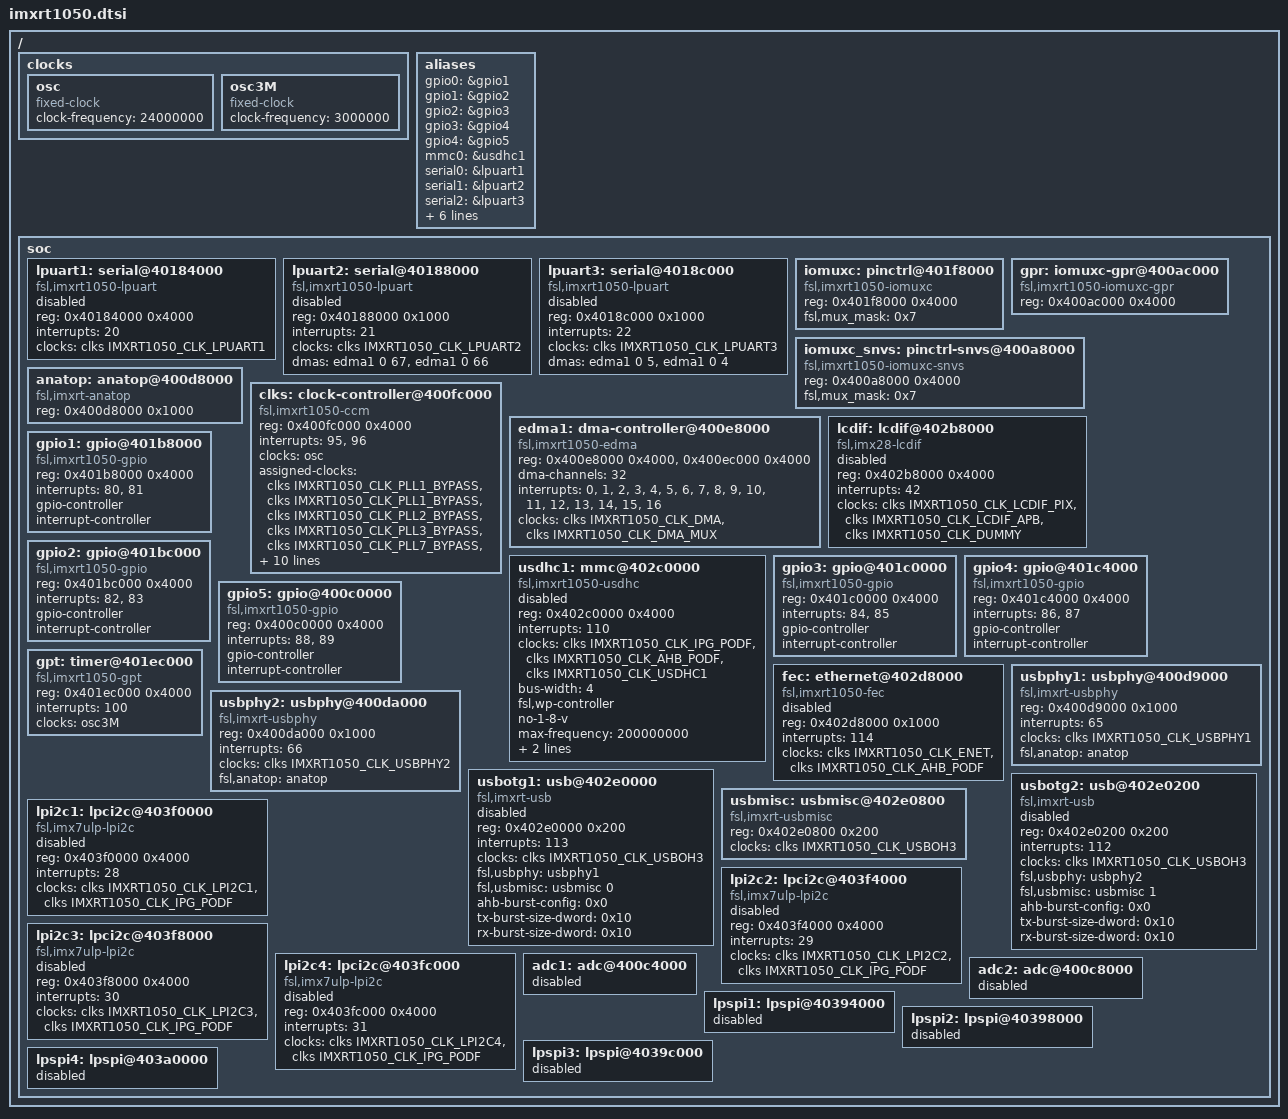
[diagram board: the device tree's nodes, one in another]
// SPDX-License-Identifier: (GPL-2.0+ OR MIT)
/*
 * Copyright (C) 2019
 * Author(s): Giulio Benetti <giulio.benetti@benettiengineering.com>
 * Copyright (C) 2023 Emcraft Systems
 * Author(s): Vladimir Skvortsov <vskvortsov@emcraft.com>
 */

#include "../../armv7-m.dtsi"
#include <dt-bindings/interrupt-controller/arm-gic.h>
#include <dt-bindings/clock/imxrt1050-clock.h>
#include <dt-bindings/gpio/gpio.h>

/ {
	#address-cells = <1>;
	#size-cells = <1>;

	clocks {
		osc: osc {
			compatible = "fixed-clock";
			#clock-cells = <0>;
			clock-frequency = <24000000>;
		};

		osc3M: osc3M {
			compatible = "fixed-clock";
			#clock-cells = <0>;
			clock-frequency = <3000000>;
		};
	};

	aliases {
		gpio0 = &gpio1;
		gpio1 = &gpio2;
		gpio2 = &gpio3;
		gpio3 = &gpio4;
		gpio4 = &gpio5;
		mmc0 = &usdhc1;
		serial0 = &lpuart1;
		serial1 = &lpuart2;
		serial2 = &lpuart3;
		usb0 = &usbotg1;
		usb1 = &usbotg2;
		usbphy0 = &usbphy1;
		usbphy1 = &usbphy2;
		adc1 = &adc1;
		adc2 = &adc2;
	};

	soc {
		lpuart1: serial@40184000 {
			compatible = "fsl,imxrt1050-lpuart", "fsl,imx7ulp-lpuart";
			reg = <0x40184000 0x4000>;
			interrupts = <20>;
			clocks = <&clks IMXRT1050_CLK_LPUART1>;
			clock-names = "ipg";
			status = "disabled";
		};

		lpuart2: serial@40188000 {
			compatible = "fsl,imxrt1050-lpuart", "fsl,imx7ulp-lpuart";
			reg = <0x40188000 0x1000>;
			interrupts = <21>;
			clocks = <&clks IMXRT1050_CLK_LPUART2>;
			clock-names = "ipg";
			dmas = <&edma1 0 67>,
			       <&edma1 0 66>;
			dma-names = "rx","tx";
			status = "disabled";
		};

		lpuart3: serial@4018c000 {
			compatible = "fsl,imxrt1050-lpuart", "fsl,imx7ulp-lpuart";
			reg = <0x4018c000 0x1000>;
			interrupts = <22>;
			clocks = <&clks IMXRT1050_CLK_LPUART3>;
			clock-names = "ipg";
			dmas = <&edma1 0 5>,
			       <&edma1 0 4>;
			dma-names = "rx","tx";
			status = "disabled";
		};

		iomuxc: pinctrl@401f8000 {
			compatible = "fsl,imxrt1050-iomuxc";
			reg = <0x401f8000 0x4000>;
			fsl,mux_mask = <0x7>;
		};

		gpr: iomuxc-gpr@400ac000 {
			compatible = "fsl,imxrt1050-iomuxc-gpr", "syscon";
			reg = <0x400ac000 0x4000>;
		};

		iomuxc_snvs: pinctrl-snvs@400a8000 {
			compatible = "fsl,imxrt1050-iomuxc-snvs";
			reg = <0x400a8000 0x4000>;
			fsl,mux_mask = <0x7>;
		};

		anatop: anatop@400d8000 {
			compatible = "fsl,imxrt-anatop", "syscon";
			reg = <0x400d8000 0x1000>;
		};

		clks: clock-controller@400fc000 {
			compatible = "fsl,imxrt1050-ccm";
			reg = <0x400fc000 0x4000>;
			interrupts = <95>, <96>;
			clocks = <&osc>;
			clock-names = "osc";
			#clock-cells = <1>;
			assigned-clocks = <&clks IMXRT1050_CLK_PLL1_BYPASS>,
				<&clks IMXRT1050_CLK_PLL1_BYPASS>,
				<&clks IMXRT1050_CLK_PLL2_BYPASS>,
				<&clks IMXRT1050_CLK_PLL3_BYPASS>,
				<&clks IMXRT1050_CLK_PLL7_BYPASS>,
				<&clks IMXRT1050_CLK_PLL3_PFD1_664_62M>,
				<&clks IMXRT1050_CLK_PLL2_PFD2_396M>;
			assigned-clock-parents = <&clks IMXRT1050_CLK_PLL1_REF_SEL>,
				<&clks IMXRT1050_CLK_PLL1_ARM>,
				<&clks IMXRT1050_CLK_PLL2_SYS>,
				<&clks IMXRT1050_CLK_PLL3>,
				<&clks IMXRT1050_CLK_PLL7>,
				<&clks IMXRT1050_CLK_PLL3>,
				<&clks IMXRT1050_CLK_PLL2_SYS>;
		};

		edma1: dma-controller@400e8000 {
			#dma-cells = <2>;
			compatible = "fsl,imxrt1050-edma";
			reg = <0x400e8000 0x4000>,
				<0x400ec000 0x4000>;
			dma-channels = <32>;
			interrupts = <0>, <1>, <2>, <3>, <4>, <5>, <6>, <7>, <8>,
				<9>, <10>, <11>, <12>, <13>, <14>, <15>, <16>;
			clock-names = "dma", "dmamux0";
			clocks = <&clks IMXRT1050_CLK_DMA>,
				 <&clks IMXRT1050_CLK_DMA_MUX>;
		};

		lcdif: lcdif@402b8000 {
			compatible = "fsl,imx28-lcdif";
			reg = <0x402b8000 0x4000>;
			interrupts = <42>;
			clocks = <&clks IMXRT1050_CLK_LCDIF_PIX>,
				 <&clks IMXRT1050_CLK_LCDIF_APB>,
				 <&clks IMXRT1050_CLK_DUMMY>;
			clock-names = "pix", "axi", "disp_axi";
			status = "disabled";
		};

		usdhc1: mmc@402c0000 {
			compatible = "fsl,imxrt1050-usdhc", "fsl,imx6sl-usdhc";
			reg = <0x402c0000 0x4000>;
			interrupts = <110>;
			clocks = <&clks IMXRT1050_CLK_IPG_PODF>,
				<&clks IMXRT1050_CLK_AHB_PODF>,
				<&clks IMXRT1050_CLK_USDHC1>;
			clock-names = "ipg", "ahb", "per";
			bus-width = <4>;
			fsl,wp-controller;
			no-1-8-v;
			max-frequency = <200000000>;
			fsl,tuning-start-tap = <20>;
			fsl,tuning-step = <2>;
			status = "disabled";
		};

		gpio1: gpio@401b8000 {
			compatible = "fsl,imxrt1050-gpio", "fsl,imx35-gpio";
			reg = <0x401b8000 0x4000>;
			interrupts = <80>, <81>;
			gpio-controller;
			#gpio-cells = <2>;
			interrupt-controller;
			#interrupt-cells = <2>;
		};

		gpio2: gpio@401bc000 {
			compatible = "fsl,imxrt1050-gpio", "fsl,imx35-gpio";
			reg = <0x401bc000 0x4000>;
			interrupts = <82>, <83>;
			gpio-controller;
			#gpio-cells = <2>;
			interrupt-controller;
			#interrupt-cells = <2>;
		};

		gpio3: gpio@401c0000 {
			compatible = "fsl,imxrt1050-gpio", "fsl,imx35-gpio";
			reg = <0x401c0000 0x4000>;
			interrupts = <84>, <85>;
			gpio-controller;
			#gpio-cells = <2>;
			interrupt-controller;
			#interrupt-cells = <2>;
		};

		gpio4: gpio@401c4000 {
			compatible = "fsl,imxrt1050-gpio", "fsl,imx35-gpio";
			reg = <0x401c4000 0x4000>;
			interrupts = <86>, <87>;
			gpio-controller;
			#gpio-cells = <2>;
			interrupt-controller;
			#interrupt-cells = <2>;
		};

		gpio5: gpio@400c0000 {
			compatible = "fsl,imxrt1050-gpio", "fsl,imx35-gpio";
			reg = <0x400c0000 0x4000>;
			interrupts = <88>, <89>;
			gpio-controller;
			#gpio-cells = <2>;
			interrupt-controller;
			#interrupt-cells = <2>;
		};

		gpt: timer@401ec000 {
			compatible = "fsl,imxrt1050-gpt", "fsl,imx6dl-gpt", "fsl,imx6sl-gpt";
			reg = <0x401ec000 0x4000>;
			interrupts = <100>;
			clocks = <&osc3M>;
			clock-names = "per";
		};

		fec: ethernet@402d8000 {
			compatible = "fsl,imxrt1050-fec", "fsl,mvf600-fec";
			reg = <0x402d8000 0x1000>;
			interrupts = <114>;
			clocks = <&clks IMXRT1050_CLK_ENET>,
				 <&clks IMXRT1050_CLK_AHB_PODF>;
			clock-names = "ipg", "ahb";
			status = "disabled";
		};

		usbphy1: usbphy@400d9000 {
			compatible = "fsl,imxrt-usbphy", "fsl,imx23-usbphy";
			reg = <0x400d9000 0x1000>;
			interrupts = <65>;
			clocks = <&clks IMXRT1050_CLK_USBPHY1>;
			fsl,anatop = <&anatop>;
		};

		usbphy2: usbphy@400da000 {
			compatible = "fsl,imxrt-usbphy", "fsl,imx23-usbphy";
			reg = <0x400da000 0x1000>;
			interrupts = <66>;
			clocks = <&clks IMXRT1050_CLK_USBPHY2>;
			fsl,anatop = <&anatop>;
		};

		usbotg1: usb@402e0000 {
			compatible = "fsl,imxrt-usb", "fsl,imx27-usb";
			reg = <0x402e0000 0x200>;
			interrupts = <113>;
			clocks = <&clks IMXRT1050_CLK_USBOH3>;
			fsl,usbphy = <&usbphy1>;
			fsl,usbmisc = <&usbmisc 0>;
			ahb-burst-config = <0x0>;
			tx-burst-size-dword = <0x10>;
			rx-burst-size-dword = <0x10>;
			status = "disabled";
		};

		usbotg2: usb@402e0200 {
			compatible = "fsl,imxrt-usb", "fsl,imx27-usb";
			reg = <0x402e0200 0x200>;
			interrupts = <112>;
			clocks = <&clks IMXRT1050_CLK_USBOH3>;
			fsl,usbphy = <&usbphy2>;
			fsl,usbmisc = <&usbmisc 1>;
			ahb-burst-config = <0x0>;
			tx-burst-size-dword = <0x10>;
			rx-burst-size-dword = <0x10>;
			status = "disabled";
		};

		usbmisc: usbmisc@402e0800 {
			#index-cells = <1>;
			compatible = "fsl,imxrt-usbmisc", "fsl,imx6q-usbmisc";
			reg = <0x402e0800 0x200>;
			clocks = <&clks IMXRT1050_CLK_USBOH3>;
		};

		lpi2c1: lpci2c@403f0000 {
			compatible = "fsl,imx7ulp-lpi2c";
			reg = <0x403f0000 0x4000>;
			interrupts = <28>;
			clocks = <&clks IMXRT1050_CLK_LPI2C1>, <&clks IMXRT1050_CLK_IPG_PODF>;
			clock-names = "per", "ipg";
			#address-cells = <1>;
			#size-cells = <0>;
			status = "disabled";
		};

		lpi2c2: lpci2c@403f4000 {
			compatible = "fsl,imx7ulp-lpi2c";
			reg = <0x403f4000 0x4000>;
			interrupts = <29>;
			clocks = <&clks IMXRT1050_CLK_LPI2C2>, <&clks IMXRT1050_CLK_IPG_PODF>;
			clock-names = "per", "ipg";
			#address-cells = <1>;
			#size-cells = <0>;
			status = "disabled";
		};

		lpi2c3: lpci2c@403f8000 {
			compatible = "fsl,imx7ulp-lpi2c";
			reg = <0x403f8000 0x4000>;
			interrupts = <30>;
			clocks = <&clks IMXRT1050_CLK_LPI2C3>, <&clks IMXRT1050_CLK_IPG_PODF>;
			clock-names = "per", "ipg";
			#address-cells = <1>;
			#size-cells = <0>;
			status = "disabled";
		};

		lpi2c4: lpci2c@403fc000 {
			compatible = "fsl,imx7ulp-lpi2c";
			reg = <0x403fc000 0x4000>;
			interrupts = <31>;
			clocks = <&clks IMXRT1050_CLK_LPI2C4>, <&clks IMXRT1050_CLK_IPG_PODF>;
			clock-names = "per", "ipg";
			#address-cells = <1>;
			#size-cells = <0>;
			status = "disabled";
		};

		adc1: adc@400c4000 {
			/* TBD */
			status = "disabled";
		};

		adc2: adc@400c8000 {
			/* TBD */
			status = "disabled";
		};

		lpspi1: lpspi@40394000 {
			/* TBD */
			status = "disabled";
		};

		lpspi2: lpspi@40398000 {
			/* TBD */
			status = "disabled";
		};

		lpspi3: lpspi@4039c000 {
			/* TBD */
			status = "disabled";
		};

		lpspi4: lpspi@403a0000 {
			/* TBD */
			status = "disabled";
		};
	};
};
